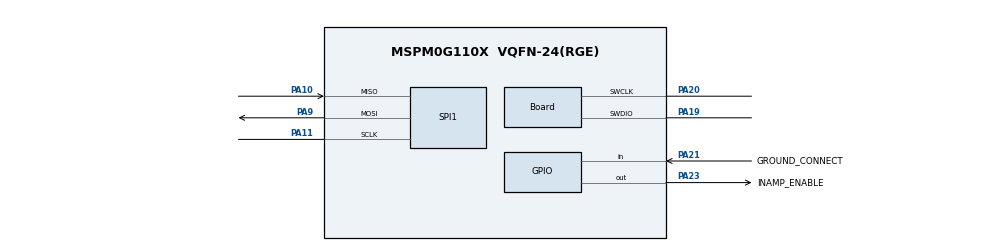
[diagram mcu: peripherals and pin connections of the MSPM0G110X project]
/**
 * @cliArgs --device "MSPM0G110X" --part "Default" --package "VQFN-24(RGE)" --product "mspm0_sdk@2.04.00.06"
 * @versions {"tool":"1.22.0+3893"}
 */

/**
 * Import the modules used in this configuration.
 */
const ADC12         = scripting.addModule("/ti/driverlib/ADC12", {}, false);
const ADC121        = ADC12.addInstance();
const GPIO          = scripting.addModule("/ti/driverlib/GPIO", {}, false);
const GPIO1         = GPIO.addInstance();
const GPIO2         = GPIO.addInstance();
const GPIO3         = GPIO.addInstance();
const GPIO4         = GPIO.addInstance();
const SPI           = scripting.addModule("/ti/driverlib/SPI", {}, false);
const SPI1          = SPI.addInstance();
const SYSCTL        = scripting.addModule("/ti/driverlib/SYSCTL");
const ProjectConfig = scripting.addModule("/ti/project_config/ProjectConfig");

/**
 * Write custom configuration values to the imported modules.
 */
const multiplier2         = system.clockTree["PLL_QDIV"];
multiplier2.multiplyValue = 5;

ADC121.$name                 = "ADC12_0";
ADC121.sampClkDiv            = "DL_ADC12_CLOCK_DIVIDE_4";
ADC121.repeatMode            = true;
ADC121.adcMem0chansel        = "DL_ADC12_INPUT_CHAN_15";
ADC121.adcMem1chansel        = "DL_ADC12_INPUT_CHAN_2";
ADC121.adcMem0_name          = "BATTERY_VOLTAGE";
ADC121.adcMem1_name          = "INAMP_DIFFERENTIAL";
ADC121.adcMem2_name          = "INAMP_REFFERENCE";
ADC121.adcMem2chansel        = "DL_ADC12_INPUT_CHAN_1";
ADC121.samplingOperationMode = "sequence";
ADC121.endAdd                = 2;
ADC121.peripheral.$assign    = "ADC0";
ADC121.adcPin2Config.$name   = "ti_driverlib_gpio_GPIOPinGeneric1";
ADC121.adcPin1Config.$name   = "ti_driverlib_gpio_GPIOPinGeneric2";

const Board                       = scripting.addModule("/ti/driverlib/Board", {}, false);
Board.peripheral.$assign          = "DEBUGSS";
Board.peripheral.swclkPin.$assign = "PA20";
Board.peripheral.swdioPin.$assign = "PA19";

GPIO1.$name                         = "LED";
GPIO1.port                          = "PORTA";
GPIO1.associatedPins.create(2);
GPIO1.associatedPins[0].$name       = "RED_LED";
GPIO1.associatedPins[0].assignedPin = "0";
GPIO1.associatedPins[0].invert      = "ENABLE";
GPIO1.associatedPins[1].$name       = "YELLOW_LED";
GPIO1.associatedPins[1].assignedPin = "1";
GPIO1.associatedPins[1].invert      = "ENABLE";

GPIO2.$name                          = "INAMP";
GPIO2.port                           = "PORTA";
GPIO2.associatedPins.create(2);
GPIO2.associatedPins[0].$name        = "INAMP_ENABLE";
GPIO2.associatedPins[0].initialValue = "SET";
GPIO2.associatedPins[0].assignedPin  = "23";
GPIO2.associatedPins[0].pin.$assign  = "PA23";
GPIO2.associatedPins[1].$name        = "INAMP_LEAD_OFF";
GPIO2.associatedPins[1].direction    = "INPUT";
GPIO2.associatedPins[1].assignedPin  = "24";

GPIO3.$name                              = "NRF";
GPIO3.associatedPins.create(3);
GPIO3.associatedPins[0].$name            = "NRF_IRQ";
GPIO3.associatedPins[0].internalResistor = "PULL_UP";
GPIO3.associatedPins[0].direction        = "INPUT";
GPIO3.associatedPins[0].assignedPin      = "2";
GPIO3.associatedPins[0].interruptEn      = true;
GPIO3.associatedPins[0].polarity         = "FALL";
GPIO3.associatedPins[1].$name            = "NRF_CE";
GPIO3.associatedPins[1].assignedPin      = "3";
GPIO3.associatedPins[2].$name            = "NRF_CS";
GPIO3.associatedPins[2].assignedPin      = "4";
GPIO3.associatedPins[2].initialValue     = "SET";

GPIO4.$name                         = "MISC";
GPIO4.associatedPins[0].$name       = "GROUND_CONNECT";
GPIO4.associatedPins[0].assignedPin = "21";
GPIO4.associatedPins[0].direction   = "INPUT";
GPIO4.associatedPins[0].pin.$assign = "PA21";

SPI1.$name                              = "SPI_NRF";
SPI1.targetBitRate                      = 1000000;
SPI1.frameFormat                        = "MOTO3";
SPI1.enabledInterrupts                  = ["IDLE","RX_FULL"];
SPI1.peripheral.sclkPin.$assign         = "PA11";
SPI1.peripheral.mosiPin.$assign         = "PA9";
SPI1.peripheral.misoPin.$assign         = "PA10";
SPI1.sclkPinConfig.direction            = scripting.forceWrite("OUTPUT");
SPI1.sclkPinConfig.onlyInternalResistor = scripting.forceWrite(false);
SPI1.sclkPinConfig.passedPeripheralType = scripting.forceWrite("Digital");
SPI1.sclkPinConfig.$name                = "ti_driverlib_gpio_GPIOPinGeneric3";
SPI1.sclkPinConfig.driveStrength        = "HIGH";
SPI1.mosiPinConfig.direction            = scripting.forceWrite("OUTPUT");
SPI1.mosiPinConfig.hideOutputInversion  = scripting.forceWrite(false);
SPI1.mosiPinConfig.onlyInternalResistor = scripting.forceWrite(false);
SPI1.mosiPinConfig.passedPeripheralType = scripting.forceWrite("Digital");
SPI1.mosiPinConfig.$name                = "ti_driverlib_gpio_GPIOPinGeneric4";
SPI1.mosiPinConfig.driveStrength        = "HIGH";
SPI1.misoPinConfig.onlyInternalResistor = scripting.forceWrite(false);
SPI1.misoPinConfig.passedPeripheralType = scripting.forceWrite("Digital");
SPI1.misoPinConfig.$name                = "ti_driverlib_gpio_GPIOPinGeneric5";

SYSCTL.peripheral.$assign = "SYSCTL";

ProjectConfig.migrationCondition = true;

/**
 * Pinmux solution for unlocked pins/peripherals. This ensures that minor changes to the automatic solver in a future
 * version of the tool will not impact the pinmux you originally saw.  These lines can be completely deleted in order to
 * re-solve from scratch.
 */
ADC121.peripheral.adcPin2.$suggestSolution   = "PA25";
ADC121.peripheral.adcPin1.$suggestSolution   = "PA26";
GPIO1.associatedPins[0].pin.$suggestSolution = "PA0";
GPIO1.associatedPins[1].pin.$suggestSolution = "PA1";
GPIO2.associatedPins[1].pin.$suggestSolution = "PA24";
GPIO3.associatedPins[0].pin.$suggestSolution = "PA2";
GPIO3.associatedPins[1].pin.$suggestSolution = "PA3";
GPIO3.associatedPins[2].pin.$suggestSolution = "PA4";
SPI1.peripheral.$suggestSolution             = "SPI0";
